# nrf54h20_engb_application register map
Vendor: Nordic Semiconductor; Series: nRF54h; File version: 1
CPU: CM33 r0p4, little endian, MPU, FPU, 3 interrupt priority bits, 480 interrupts, 8 SAU regions
Registers are 32-bit, read-write, reset 0x0 unless marked. A register's access mark holds for its fields unless they carry their own. Offsets are from the block's base; [hi:lo] are bit positions; 'fields as' and 'values as' point back to an identical list.

## GLOBAL_TDDCONF_NS — TDDCONF 0
Base 0xBF001000
Same registers: GLOBAL_TDDCONF_S 0xBF001000 (alternate view of GLOBAL_TDDCONF_NS)
0x400 SYSPWRUPREQ — System power-up request
  [0] ACTIVE — Activate power-up request
    0=NotActive (Power-up request not active); 1=Active (Power-up request active)
0x404 DBGPWRUPREQ — Debug power-up request
  fields as SYSPWRUPREQ
0x408 TRACEPORTSPEED — Trace port trace clock speed
  [1:0] SPEED — Trace clock speed
    0=Speed80MHz; 1=Speed40MHz; 2=Speed20MHz; 3=Speed10MHz
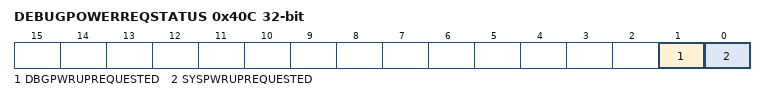
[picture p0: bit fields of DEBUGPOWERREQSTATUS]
0x40C DEBUGPOWERREQSTATUS ro — Combined effective system status of both SWJ-DP and TDDCONF registers originated power requests
  [1] DBGPWRUPREQUESTED — Debug domain powerup request status
    0=NoPowerReq (Power not requested); 1=Power requested
  [0] SYSPWRUPREQUESTED — System powerup request status
    0=NoPowerReq (Power not requested); 1=Power requested

## CPUC_S — CM33 SubSystem
Base 0xE0080000
0x100 EVENTS_FPUIOC — An invalid operation exception has occurred in the FPU.
  [0] EVENTS_FPUIOC
    0=NotGenerated (Event not generated); 1=Generated (Event generated)
0x104 EVENTS_FPUDZC — A floating-point divide-by-zero exception has occurred in the FPU.
  [0] EVENTS_FPUDZC
    values as EVENTS_FPUIOC.EVENTS_FPUIOC
0x108 EVENTS_FPUOFC — A floating-point overflow exception has occurred in the FPU.
  [0] EVENTS_FPUOFC
    values as EVENTS_FPUIOC.EVENTS_FPUIOC
0x10C EVENTS_FPUUFC — A floating-point underflow exception has occurred in the FPU.
  [0] EVENTS_FPUUFC
    values as EVENTS_FPUIOC.EVENTS_FPUIOC
0x110 EVENTS_FPUIXC — A floating-point inexact exception has occurred in the FPU.
  [0] EVENTS_FPUIXC
    values as EVENTS_FPUIOC.EVENTS_FPUIOC
0x114 EVENTS_FPUIDC — A floating-point input denormal exception has occurred in the FPU.
  [0] EVENTS_FPUIDC
    values as EVENTS_FPUIOC.EVENTS_FPUIOC
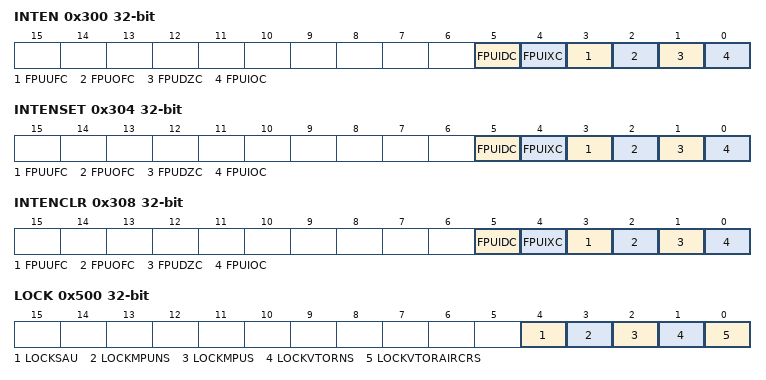
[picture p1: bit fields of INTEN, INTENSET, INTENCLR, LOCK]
0x300 INTEN — Enable or disable interrupt
  [all] fields
    0=Disabled; 1=Enabled
  [5] FPUIDC — Enable or disable interrupt for event FPUIDC
  [4] FPUIXC — Enable or disable interrupt for event FPUIXC
  [3] FPUUFC — Enable or disable interrupt for event FPUUFC
  [2] FPUOFC — Enable or disable interrupt for event FPUOFC
  [1] FPUDZC — Enable or disable interrupt for event FPUDZC
  [0] FPUIOC — Enable or disable interrupt for event FPUIOC
0x304 INTENSET — Enable interrupt
  [all] fields
    on read: 0=Disabled (Read: Disabled); 1=Enabled (Read: Enabled) | on write: 1=Set (Enable)
  [5] FPUIDC — Write '1' to enable interrupt for event FPUIDC
  [4] FPUIXC — Write '1' to enable interrupt for event FPUIXC
  [3] FPUUFC — Write '1' to enable interrupt for event FPUUFC
  [2] FPUOFC — Write '1' to enable interrupt for event FPUOFC
  [1] FPUDZC — Write '1' to enable interrupt for event FPUDZC
  [0] FPUIOC — Write '1' to enable interrupt for event FPUIOC
0x308 INTENCLR — Disable interrupt
  [all] fields
    on read: 0=Disabled (Read: Disabled); 1=Enabled (Read: Enabled) | on write: 1=Clear (Disable)
  [5] FPUIDC — Write '1' to disable interrupt for event FPUIDC
  [4] FPUIXC — Write '1' to disable interrupt for event FPUIXC
  [3] FPUUFC — Write '1' to disable interrupt for event FPUUFC
  [2] FPUOFC — Write '1' to disable interrupt for event FPUOFC
  [1] FPUDZC — Write '1' to disable interrupt for event FPUDZC
  [0] FPUIOC — Write '1' to disable interrupt for event FPUIOC
0x500 LOCK — Register to lock the certain parts of the CPU from being modified.
  [4] LOCKSAU — Locks the Security Attribution Unit (SAU)
    0=NotLocked (SAU registers can be changed.); 1=Locked (Prevents changes to SAU registers.)
  [3] LOCKMPUNS — Locks the Memory Protection Unit (MPU) for non secure mode.
    0=NotLocked (MPU registers can be changed.); 1=Locked (Prevents changes to MPU registers.)
  [2] LOCKMPUS — Locks the Memory Protection Unit (MPU) for secure mode.
    values as LOCKMPUNS
  [1] LOCKVTORNS — Locks the Vector table Offset Register (VTOR) for non-secure mode.
    0=NotLocked (VTOR can be changed.); 1=Locked (Prevents changes to VTOR.)
  [0] LOCKVTORAIRCRS — Locks both the Vector table Offset Register (VTOR) and Application Interrupt and Reset Control Register (AIRCR) for secure mode.
    0=NotLocked (Both VTOR and AIRCR can be changed.); 1=Locked (Prevents changes to both VTOR and AIRCR.)
0x504 CPUID ro — The identifier for the CPU in this subsystem.
  [31:0] CPUID — The CPU identifier.
